# ESP32S31_RADIO register map
Vendor: Espressif; Series: ESP32-S31; File version: 3.52
Registers are 32-bit, read-write, no defined reset value unless marked. A register's access mark holds for its fields unless they carry their own. Offsets are from the block's base; [hi:lo] are bit positions; {n}, {i} and the like mark numbered series.

## IEEE802154_MAC — Dedicated ESP32-S31 IEEE 802.15.4 MAC aperture at 0x20103000. This selective foundation publishes only register geometry exercised by the pinned public common/chip LL accessors. The public struct and register headers still carry TODO ZB-93 pending an authoritative regdesc CSV, so untouched DTM, timing, debug-selector and modem-sleep words remain deliberately absent and no reset values are claimed.
Base 0x20103000
0x00 COMMAND wo — Write-only IEEE 802.15.4 MAC command opcode. The public common LL constrains commands to the listed values.
  [7:0] OPCODE
    on write: 65=TX_START; 66=RX_START; 67=CCA_TX_START; 68=ED_START; 69=STOP; 70=TEST_TX_START; 71=TEST_RX_START; 72=TEST_STOP; 76=TIMER0_START; 77=TIMER0_STOP; 78=TIMER1_START; 79=TIMER1_STOP
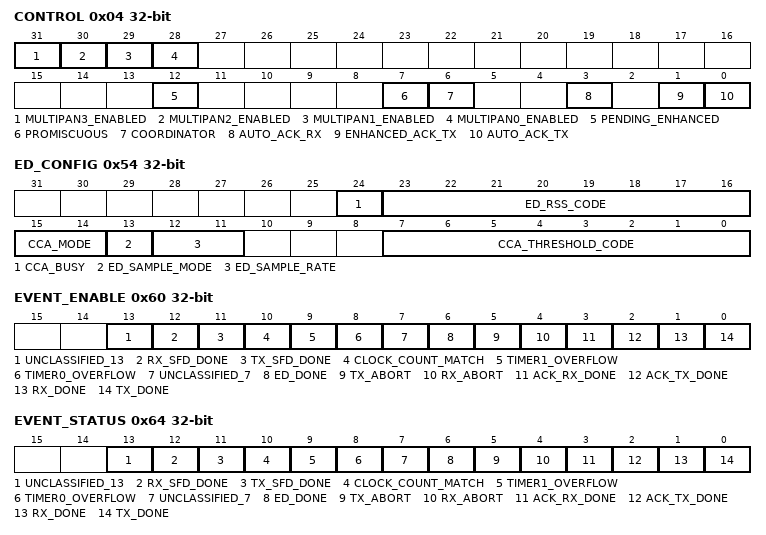
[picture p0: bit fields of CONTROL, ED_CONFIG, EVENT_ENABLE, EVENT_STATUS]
0x04 CONTROL — Selected MAC policy bits mutated by public common LL accessors. Unused control bits remain absent.
  [31] MULTIPAN3_ENABLED — Enable public multipan context three.
  [30] MULTIPAN2_ENABLED — Enable public multipan context two.
  [29] MULTIPAN1_ENABLED — Enable public multipan context one.
  [28] MULTIPAN0_ENABLED — Enable public multipan context zero.
  [12] PENDING_ENHANCED — Boolean pending-mode selector used by the current public LL. The wider public pending-mode enum is not encoded in this one-bit field.
  [7] PROMISCUOUS
  [6] COORDINATOR
  [3] AUTO_ACK_RX
  [1] ENHANCED_ACK_TX
  [0] AUTO_ACK_TX
{0x8+0x10*i} MULTIPAN{i}_SHORT_ADDRESS (i=0..3) — Sixteen-bit short address for one public multipan context.
  [15:0] ADDRESS
{0xC+0x10*i} MULTIPAN{i}_PAN_ID (i=0..3) — Sixteen-bit PAN identifier for one public multipan context.
  [15:0] PAN_ID
{0x10+0x10*i} MULTIPAN{i}_EXTENDED_ADDRESS_LOW (i=0..3) — Extended-address bytes zero through three packed little-endian by the public common LL.
  [31:0] ADDRESS_WORD
{0x14+0x10*i} MULTIPAN{i}_EXTENDED_ADDRESS_HIGH (i=0..3) — Extended-address bytes four through seven packed little-endian by the public common LL.
  [31:0] ADDRESS_WORD
0x48 CHANNEL — Selected primary frequency code. Other multi-channel and frequency-hop controls declared by the struct are not used by the public common LL and remain absent.
  [7:0] FREQUENCY_CODE — Eight-bit code read and written by ieee802154_ll_get_freq/set_freq; this register model does not equate it to an IEEE channel number.
0x4C TX_POWER — Eight-bit transmit-power code written through a preserving bitfield update by the public common LL.
  [7:0] POWER_CODE — Raw eight-bit hardware code; no dBm conversion is claimed at the register boundary.
0x50 ED_DURATION — Energy-detection duration field written by the public common LL. The adjacent delay field is not used there and remains absent.
  [23:0] DURATION — Twenty-four-bit physical field. The current public setter accepts only a uint16_t and therefore exercises a strict subset of its declared range.
0x54 ED_CONFIG — Energy-detection and clear-channel-assessment configuration plus read-only result fields used by the public common LL. The pinned reg macros call bits 12:11 ED_SAMPLE_MODE and bit 13 DIS_ED_POWER_SEL, while the pinned struct/common LL operate them as ED_SAMPLE_RATE and ED_SAMPLE_MODE respectively; this model follows the operational struct/common-LL pair and leaves the naming conflict explicit.
  [24] CCA_BUSY ro
  [23:16] ED_RSS_CODE ro — Eight-bit result returned as int8_t by the public common LL.
  [15:14] CCA_MODE
    on write: 0=CARRIER; 1=ENERGY_DETECTION; 2=CARRIER_OR_ENERGY_DETECTION; 3=CARRIER_AND_ENERGY_DETECTION
  [13] ED_SAMPLE_MODE
    on write: 0=MAXIMUM; 1=AVERAGE
  [12:11] ED_SAMPLE_RATE
    on write: 0=ONE_PER_US; 1=TWO_PER_US; 2=FOUR_PER_US; 3=EIGHT_PER_US
  [7:0] CCA_THRESHOLD_CODE — Eight-bit code written from an int8_t; signed physical units are intentionally left to the HAL.
0x5C ACK_TIMEOUT — Sixteen-bit acknowledgment timeout read and written by the public common LL. Units are not assigned by this register model.
  [15:0] TIMEOUT
0x60 EVENT_ENABLE — Individual event enables mutated by the public common LL. Bits seven and thirteen remain physically observable but have no assigned vendor event semantics.
  [13] UNCLASSIFIED_13 — Physically present event-enable bit without an assigned public vendor event.
  [12] RX_SFD_DONE
  [11] TX_SFD_DONE
  [10] CLOCK_COUNT_MATCH
  [9] TIMER1_OVERFLOW
  [8] TIMER0_OVERFLOW
  [7] UNCLASSIFIED_7 — Physically present event-enable bit without an assigned public vendor event.
  [6] ED_DONE
  [5] TX_ABORT
  [4] RX_ABORT
  [3] ACK_RX_DONE
  [2] ACK_TX_DONE
  [1] RX_DONE
  [0] TX_DONE
0x64 EVENT_STATUS write-1-clears — Individual event status bits read by the public LL. The target-reviewed overlay assigns the read-write W1C contract for the applicable ESP32-S31 revision; bits seven and thirteen have no assigned vendor event semantics.
  [13] UNCLASSIFIED_13 — Physically present event-status bit without an assigned public vendor event.
  [12] RX_SFD_DONE
  [11] TX_SFD_DONE
  [10] CLOCK_COUNT_MATCH
  [9] TIMER1_OVERFLOW
  [8] TIMER0_OVERFLOW
  [7] UNCLASSIFIED_7 — Physically present event-status bit without an assigned public vendor event.
  [6] ED_DONE
  [5] TX_ABORT
  [4] RX_ABORT
  [3] ACK_RX_DONE
  [2] ACK_TX_DONE
  [1] RX_DONE
  [0] TX_DONE
0x68 RX_ABORT_ENABLE — Low thirty-one receive-abort enable bits mutated by public LL accessors. Only the finite abort-reason values named by the LL are semantically classified.
  [30:0] EVENTS
    on write: 0=NONE (Mask every receive-abort reason.); 0x28000=RUNTIME_BASELINE (Reviewed receive-abort baseline used by the runtime ISR.); 0x3800000=ED_OPERATION_REASONS (Enable ED abort, ED stop, and ED coexistence rejection for one finite ED or CCA operation.)
0x6C PENDING_CONFIG — Selected outgoing acknowledgment frame-pending bit. The untouched timeout field remains absent.
  [0] FRAME_PENDING
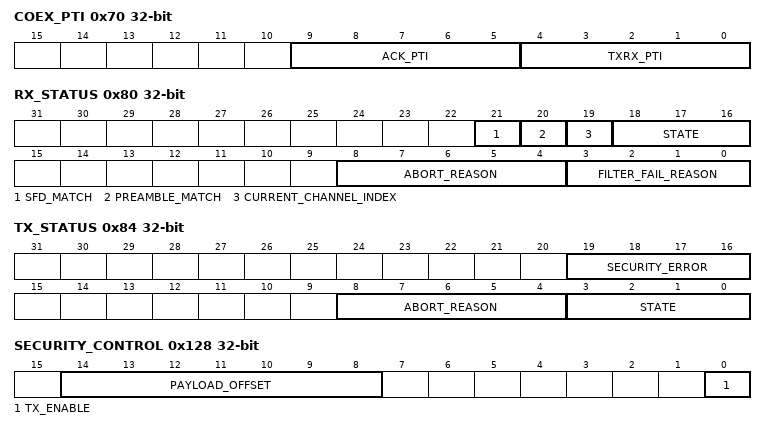
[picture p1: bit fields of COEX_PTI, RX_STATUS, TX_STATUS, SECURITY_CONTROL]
0x70 COEX_PTI — Selected coexistence priority fields. The public disable-coexistence helper writes value three to each through two preserving field updates. Other antenna and RF controls remain absent.
  [9:5] ACK_PTI, [4:0] TXRX_PTI
0x78 TX_ABORT_ENABLE — Low thirty-one transmit-abort enable bits mutated by public LL accessors. Only the finite abort-reason values named by the LL are semantically classified.
  [30:0] EVENTS
    on write: 0=NONE (Mask every transmit-abort reason.); 0x1868000=RUNTIME_BASELINE (Reviewed transmit-abort baseline used by the runtime ISR.)
0x7C ENHANCED_ACK_NOTIFY wo — Write-only enhanced-ack generation-done notification word. The public common LL writes the complete value one; trigger/clear behavior is not inferred.
  [31:0] NOTIFY_IMAGE
0x80 RX_STATUS ro — Receive status snapshot returned whole by the public common LL; selected subfields are independently named by the struct and accessor set.
  [21] SFD_MATCH
  [20] PREAMBLE_MATCH
  [19] CURRENT_CHANNEL_INDEX
  [18:16] STATE — Three-bit receive state. The public LL only establishes that value one is RECEIVE_SFD and tests for later states with a greater-than comparison.
  [8:4] ABORT_REASON
    on read: 1=RX_STOP; 2=SFD_TIMEOUT; 3=CRC_ERROR; 4=INVALID_LENGTH; 5=FILTER_FAIL; 6=NO_RSS; 7=COEX_BREAK; 8=UNEXPECTED_ACK; 9=RX_RESTART; 16=TX_ACK_TIMEOUT; 17=TX_ACK_STOP; 18=TX_ACK_COEX_BREAK; 19=ENHANCED_ACK_SECURITY_ERROR; 24=ED_ABORT; 25=ED_STOP; 26=ED_COEX_REJECT
  [3:0] FILTER_FAIL_REASON
0x84 TX_STATUS ro — Transmit status snapshot returned whole by the public common LL; abort and security-error subfields have public finite reason enums.
  [19:16] SECURITY_ERROR
    on read: 1=FRAME_CONTROL_NOT_SET; 2=RESERVED_SECURITY_LEVEL; 3=HEADER_PARSE; 4=PAYLOAD_ERROR; 5=FRAME_COUNTER_SUPPRESSION
  [8:4] ABORT_REASON
    on read: 1=RX_ACK_STOP; 2=RX_ACK_SFD_TIMEOUT; 3=RX_ACK_CRC_ERROR; 4=RX_ACK_INVALID_LENGTH; 5=RX_ACK_FILTER_FAIL; 6=RX_ACK_NO_RSS; 7=RX_ACK_COEX_BREAK; 8=RX_ACK_TYPE_NOT_ACK; 9=RX_ACK_RESTART; 16=RX_ACK_TIMEOUT; 17=TX_STOP; 18=TX_COEX_BREAK; 19=TX_SECURITY_ERROR; 24=CCA_FAILED; 25=CCA_BUSY
  [3:0] STATE
0xA8 TIMER0_THRESHOLD wo — Complete timer-zero threshold word written by the public common LL.
0xAC TIMER0_VALUE ro — Complete timer-zero value word read by the public common LL.
0xB0 TIMER1_THRESHOLD wo — Complete timer-one threshold word written by the public common LL.
0xB4 TIMER1_VALUE ro — Complete timer-one value word read by the public common LL.
0xD0 TX_DMA_ADDRESS wo — Complete transmit frame-buffer address written by the public common LL. Address validity and buffer lifetime remain HAL responsibilities.
0xE0 RX_DMA_ADDRESS wo — Complete receive frame-buffer address written by the public common LL. Address validity and buffer lifetime remain HAL responsibilities.
0x110 RXON_DELAY — Receive-on delay image updated by the pinned public ESP32-S31 IEEE 802.15.4 initializer. The literal value 50 is reviewed; physical units remain outside the PAC.
  [10:0] RXON_DELAY — Eleven-bit preserving field written with literal 50 after the shared BTBB transmit-on delay override.
0x128 SECURITY_CONTROL — Transmit-security enable and payload-offset fields used by the public common LL.
  [14:8] PAYLOAD_OFFSET, [0] TX_ENABLE
0x12C SECURITY_ADDRESS_LOW wo — Security extended-address bytes zero through three packed little-endian by the public common LL.
  [31:0] ADDRESS_WORD
0x130 SECURITY_ADDRESS_HIGH wo — Security extended-address bytes four through seven packed little-endian by the public common LL.
  [31:0] ADDRESS_WORD
{0x134+4i} SECURITY_KEY{i} (i=0..3) wo — One little-endian four-byte word of the sixteen-byte transmit-security key written by the public common LL. Key lifecycle and zeroization remain HAL obligations.
  [31:0] KEY_WORD
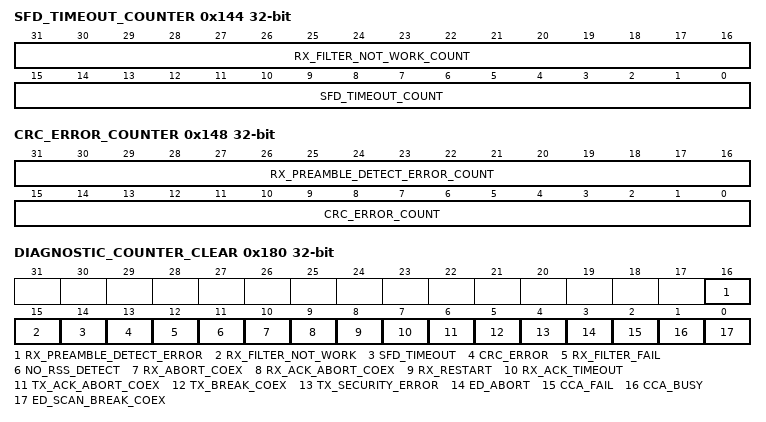
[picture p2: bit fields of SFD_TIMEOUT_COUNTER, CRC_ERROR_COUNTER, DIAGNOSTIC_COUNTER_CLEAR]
0x144 SFD_TIMEOUT_COUNTER ro — Two read-only diagnostic counters independently read by the common and ESP32-S31 LL headers.
  [31:16] RX_FILTER_NOT_WORK_COUNT, [15:0] SFD_TIMEOUT_COUNT
0x148 CRC_ERROR_COUNTER ro — Two read-only diagnostic counters independently read by the common and ESP32-S31 LL headers.
  [31:16] RX_PREAMBLE_DETECT_ERROR_COUNT, [15:0] CRC_ERROR_COUNT
0x14C ED_ABORT_COUNTER ro
  [15:0] COUNT
0x150 CCA_FAIL_COUNTER ro
  [15:0] COUNT
0x154 RX_FILTER_FAIL_COUNTER ro
  [15:0] COUNT
0x158 NO_RSS_DETECT_COUNTER ro
  [15:0] COUNT
0x15C RX_ABORT_COEX_COUNTER ro
  [15:0] COUNT
0x160 RX_RESTART_COUNTER ro
  [15:0] COUNT
0x164 TX_ACK_ABORT_COEX_COUNTER ro
  [15:0] COUNT
0x168 ED_SCAN_BREAK_COEX_COUNTER ro
  [15:0] COUNT
0x16C RX_ACK_ABORT_COEX_COUNTER ro
  [15:0] COUNT
0x170 RX_ACK_TIMEOUT_COUNTER ro
  [15:0] COUNT
0x174 TX_BREAK_COEX_COUNTER ro
  [15:0] COUNT
0x178 TX_SECURITY_ERROR_COUNTER ro
  [15:0] COUNT
0x17C CCA_BUSY_COUNTER ro
  [15:0] COUNT
0x180 DIAGNOSTIC_COUNTER_CLEAR wo — Write-only clear bitmap for the seventeen named diagnostic counters. The public common LL writes a complete caller-supplied image; no self-clearing timing is inferred.
  [16] RX_PREAMBLE_DETECT_ERROR, [15] RX_FILTER_NOT_WORK, [14] SFD_TIMEOUT, [13] CRC_ERROR, [12] RX_FILTER_FAIL, [11] NO_RSS_DETECT, [10] RX_ABORT_COEX, [9] RX_ACK_ABORT_COEX, [8] RX_RESTART, [7] RX_ACK_TIMEOUT, [6] TX_ACK_ABORT_COEX, [5] TX_BREAK_COEX, [4] TX_SECURITY_ERROR, [3] ED_ABORT, [2] CCA_FAIL, [1] CCA_BUSY, [0] ED_SCAN_BREAK_COEX
